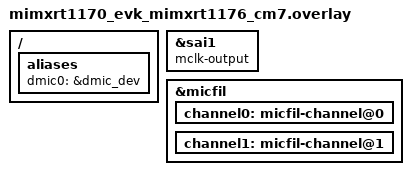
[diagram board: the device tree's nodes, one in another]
/*
 * Copyright 2025 NXP
 *
 * SPDX-License-Identifier: Apache-2.0
 */
/ {
	aliases {
		dmic0 = &dmic_dev;
	};
};

&sai1 {
	mclk-output;
};

dmic_dev: &micfil {
	channel0: micfil-channel@0 {
		status = "okay";
	};

	channel1: micfil-channel@1 {
		status = "okay";
	};
};
